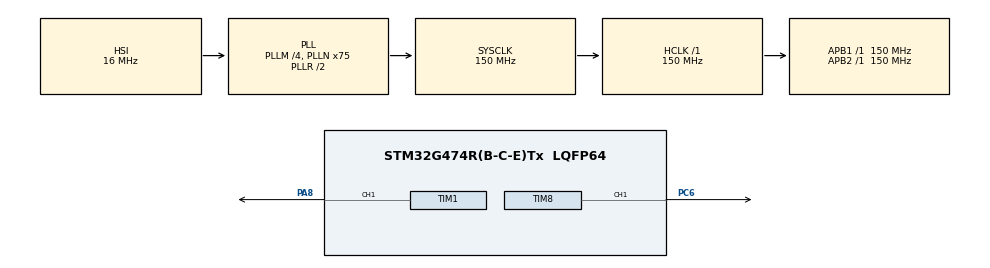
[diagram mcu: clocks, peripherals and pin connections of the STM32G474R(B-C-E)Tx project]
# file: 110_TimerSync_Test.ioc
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Mcu.Family=STM32G4
Mcu.Name=STM32G474R(B-C-E)Tx
Mcu.Package=LQFP64
NVIC.PriorityGroup=NVIC_PRIORITYGROUP_4
PA8.GPIO_ModeDefaultPP=GPIO_MODE_AF_PP
PA8.GPIO_PuPd=GPIO_PULLUP
PA8.Signal=S_TIM1_CH1
PC6.GPIO_ModeDefaultPP=GPIO_MODE_AF_PP
PC6.GPIO_PuPd=GPIO_NOPULL
PC6.Signal=S_TIM8_CH1
PF0-OSC_IN.Mode=HSE-External-Oscillator
PF0-OSC_IN.Signal=RCC_OSC_IN
PF1-OSC_OUT.Mode=HSE-External-Oscillator
PF1-OSC_OUT.Signal=RCC_OSC_OUT
ProjectManager.HeapSize=0x200
ProjectManager.StackSize=0x400
ProjectManager.TargetToolchain=STM32CubeIDE
RCC.ADC12Freq_Value=150000000
RCC.ADC345Freq_Value=150000000
RCC.AHBFreq_Value=150000000
RCC.APB1Freq_Value=150000000
RCC.APB1TimFreq_Value=150000000
RCC.APB2Freq_Value=150000000
RCC.APB2TimFreq_Value=150000000
RCC.CortexFreq_Value=150000000
RCC.EXTERNAL_CLOCK_VALUE=12288000
RCC.HCLKFreq_Value=150000000
RCC.HSE_VALUE=48000000
RCC.HSI48_VALUE=48000000
RCC.HSI_VALUE=16000000
RCC.LSE_VALUE=32768
RCC.PLLM=RCC_PLLM_DIV4
RCC.PLLN=75
RCC.SYSCLKFreq_VALUE=150000000
RCC.SYSCLKSource=RCC_SYSCLKSOURCE_PLLCLK
RCC.USBFreq_Value=150000000
RCC.VCOOutputFreq_Value=300000000
SH.S_TIM1_CH1.0=TIM1_CH1,PWM Generation1 CH1
SH.S_TIM8_CH1.0=TIM8_CH1,PWM Generation1 CH1
TIM1.Channel-PWM\ Generation1\ CH1=TIM_CHANNEL_1
TIM1.CounterMode=TIM_COUNTERMODE_UP
TIM1.OCIdleState_1=TIM_OCIDLESTATE_RESET
TIM1.OCPolarity_1=TIM_OCPOLARITY_LOW
TIM1.PeriodNoDither=1000-1
TIM1.Prescaler=150-1
TIM1.PulseNoDither_1=500-1
TIM1.TIM_MasterOutputTrigger=TIM_TRGO_UPDATE
TIM1.TIM_MasterOutputTrigger2=TIM_TRGO2_RESET
TIM8.Channel-PWM\ Generation1\ CH1=TIM_CHANNEL_1
TIM8.OCIdleState_1=TIM_OCIDLESTATE_RESET
TIM8.OCPolarity_1=TIM_OCPOLARITY_HIGH
TIM8.PeriodNoDither=1000-1
TIM8.Prescaler=15-1
TIM8.PulseNoDither_1=500-1
TIM8.TIM_MasterOutputTrigger=TIM_TRGO_RESET
VP_SYS_VS_DBSignals.Mode=DisableDeadBatterySignals
VP_TIM1_VS_ClockSourceINT.Mode=Internal
VP_TIM8_VS_ClockSourceINT.Mode=Internal
board=custom

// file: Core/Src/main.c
/* USER CODE BEGIN Header */
/**
  ******************************************************************************
  * @file           : main.c
  * @brief          : Main program body
  ******************************************************************************
  * @attention
  *
  * Copyright (c) 2024 STMicroelectronics.
  * All rights reserved.
  *
  * This software is licensed under terms that can be found in the LICENSE file
  * in the root directory of this software component.
  * If no LICENSE file comes with this software, it is provided AS-IS.
  *
  ******************************************************************************
  */
/* USER CODE END Header */
#include "main.h"

TIM_HandleTypeDef htim1;
TIM_HandleTypeDef htim8;

void SystemClock_Config(void);
static void MX_GPIO_Init(void);
static void MX_TIM1_Init(void);
static void MX_TIM8_Init(void);

int main(void)
{

  /* MCU Configuration--------------------------------------------------------*/

  /* Reset of all peripherals, Initializes the Flash interface and the Systick. */
  HAL_Init();

  /* Configure the system clock */
  SystemClock_Config();

  /* Initialize all configured peripherals */
  MX_GPIO_Init();
  MX_TIM1_Init();
  MX_TIM8_Init();
  /* USER CODE BEGIN 2 */
  HAL_TIM_PWM_Start(&htim8, TIM_CHANNEL_1); // Slave Timer
  HAL_Delay(20);
  HAL_TIM_PWM_Start(&htim1, TIM_CHANNEL_1); // Master Timer
  /* USER CODE END 2 */

  /* Infinite loop */
  while (1)
  {

  }
}

void SystemClock_Config(void)
{
  RCC_OscInitTypeDef RCC_OscInitStruct = {0};
  RCC_ClkInitTypeDef RCC_ClkInitStruct = {0};

  /** Configure the main internal regulator output voltage
  */
  HAL_PWREx_ControlVoltageScaling(PWR_REGULATOR_VOLTAGE_SCALE1);

  /** Initializes the RCC Oscillators according to the specified parameters
  * in the RCC_OscInitTypeDef structure.
  */
  RCC_OscInitStruct.OscillatorType = RCC_OSCILLATORTYPE_HSI;
  RCC_OscInitStruct.HSIState = RCC_HSI_ON;
  RCC_OscInitStruct.HSICalibrationValue = RCC_HSICALIBRATION_DEFAULT;
  RCC_OscInitStruct.PLL.PLLState = RCC_PLL_ON;
  RCC_OscInitStruct.PLL.PLLSource = RCC_PLLSOURCE_HSI;
  RCC_OscInitStruct.PLL.PLLM = RCC_PLLM_DIV4;
  RCC_OscInitStruct.PLL.PLLN = 75;
  RCC_OscInitStruct.PLL.PLLP = RCC_PLLP_DIV2;
  RCC_OscInitStruct.PLL.PLLQ = RCC_PLLQ_DIV2;
  RCC_OscInitStruct.PLL.PLLR = RCC_PLLR_DIV2;
  if (HAL_RCC_OscConfig(&RCC_OscInitStruct) != HAL_OK)
  {
    Error_Handler();
  }

  /** Initializes the CPU, AHB and APB buses clocks
  */
  RCC_ClkInitStruct.ClockType = RCC_CLOCKTYPE_HCLK|RCC_CLOCKTYPE_SYSCLK
                              |RCC_CLOCKTYPE_PCLK1|RCC_CLOCKTYPE_PCLK2;
  RCC_ClkInitStruct.SYSCLKSource = RCC_SYSCLKSOURCE_PLLCLK;
  RCC_ClkInitStruct.AHBCLKDivider = RCC_SYSCLK_DIV1;
  RCC_ClkInitStruct.APB1CLKDivider = RCC_HCLK_DIV1;
  RCC_ClkInitStruct.APB2CLKDivider = RCC_HCLK_DIV1;

  if (HAL_RCC_ClockConfig(&RCC_ClkInitStruct, FLASH_LATENCY_4) != HAL_OK)
  {
    Error_Handler();
  }
}

static void MX_TIM1_Init(void)
{

  TIM_ClockConfigTypeDef sClockSourceConfig = {0};
  TIM_MasterConfigTypeDef sMasterConfig = {0};
  TIM_OC_InitTypeDef sConfigOC = {0};
  TIM_BreakDeadTimeConfigTypeDef sBreakDeadTimeConfig = {0};

  htim1.Instance = TIM1;
  htim1.Init.Prescaler = 150-1;
  htim1.Init.CounterMode = TIM_COUNTERMODE_UP;
  htim1.Init.Period = 999;
  htim1.Init.ClockDivision = TIM_CLOCKDIVISION_DIV1;
  htim1.Init.RepetitionCounter = 0;
  htim1.Init.AutoReloadPreload = TIM_AUTORELOAD_PRELOAD_DISABLE;
  if (HAL_TIM_Base_Init(&htim1) != HAL_OK)
  {
    Error_Handler();
  }
  sClockSourceConfig.ClockSource = TIM_CLOCKSOURCE_INTERNAL;
  if (HAL_TIM_ConfigClockSource(&htim1, &sClockSourceConfig) != HAL_OK)
  {
    Error_Handler();
  }
  if (HAL_TIM_PWM_Init(&htim1) != HAL_OK)
  {
    Error_Handler();
  }
  sMasterConfig.MasterOutputTrigger = TIM_TRGO_UPDATE;
  sMasterConfig.MasterOutputTrigger2 = TIM_TRGO2_RESET;
  sMasterConfig.MasterSlaveMode = TIM_MASTERSLAVEMODE_DISABLE;
  if (HAL_TIMEx_MasterConfigSynchronization(&htim1, &sMasterConfig) != HAL_OK)
  {
    Error_Handler();
  }
  sConfigOC.OCMode = TIM_OCMODE_PWM1;
  sConfigOC.Pulse = 499;
  sConfigOC.OCPolarity = TIM_OCPOLARITY_LOW;
  sConfigOC.OCNPolarity = TIM_OCNPOLARITY_HIGH;
  sConfigOC.OCFastMode = TIM_OCFAST_DISABLE;
  sConfigOC.OCIdleState = TIM_OCIDLESTATE_RESET;
  sConfigOC.OCNIdleState = TIM_OCNIDLESTATE_RESET;
  if (HAL_TIM_PWM_ConfigChannel(&htim1, &sConfigOC, TIM_CHANNEL_1) != HAL_OK)
  {
    Error_Handler();
  }
  sBreakDeadTimeConfig.OffStateRunMode = TIM_OSSR_DISABLE;
  sBreakDeadTimeConfig.OffStateIDLEMode = TIM_OSSI_DISABLE;
  sBreakDeadTimeConfig.LockLevel = TIM_LOCKLEVEL_OFF;
  sBreakDeadTimeConfig.DeadTime = 0;
  sBreakDeadTimeConfig.BreakState = TIM_BREAK_DISABLE;
  sBreakDeadTimeConfig.BreakPolarity = TIM_BREAKPOLARITY_HIGH;
  sBreakDeadTimeConfig.BreakFilter = 0;
  sBreakDeadTimeConfig.BreakAFMode = TIM_BREAK_AFMODE_INPUT;
  sBreakDeadTimeConfig.Break2State = TIM_BREAK2_DISABLE;
  sBreakDeadTimeConfig.Break2Polarity = TIM_BREAK2POLARITY_HIGH;
  sBreakDeadTimeConfig.Break2Filter = 0;
  sBreakDeadTimeConfig.Break2AFMode = TIM_BREAK_AFMODE_INPUT;
  sBreakDeadTimeConfig.AutomaticOutput = TIM_AUTOMATICOUTPUT_DISABLE;
  if (HAL_TIMEx_ConfigBreakDeadTime(&htim1, &sBreakDeadTimeConfig) != HAL_OK)
  {
    Error_Handler();
  }
  HAL_TIM_MspPostInit(&htim1);

}

static void MX_TIM8_Init(void)
{

  TIM_ClockConfigTypeDef sClockSourceConfig = {0};
  TIM_MasterConfigTypeDef sMasterConfig = {0};
  TIM_OC_InitTypeDef sConfigOC = {0};
  TIM_BreakDeadTimeConfigTypeDef sBreakDeadTimeConfig = {0};

  htim8.Instance = TIM8;
  htim8.Init.Prescaler = 15-1;
  htim8.Init.CounterMode = TIM_COUNTERMODE_UP;
  htim8.Init.Period = 999;
  htim8.Init.ClockDivision = TIM_CLOCKDIVISION_DIV1;
  htim8.Init.RepetitionCounter = 0;
  htim8.Init.AutoReloadPreload = TIM_AUTORELOAD_PRELOAD_DISABLE;
  if (HAL_TIM_Base_Init(&htim8) != HAL_OK)
  {
    Error_Handler();
  }
  sClockSourceConfig.ClockSource = TIM_CLOCKSOURCE_INTERNAL;
  if (HAL_TIM_ConfigClockSource(&htim8, &sClockSourceConfig) != HAL_OK)
  {
    Error_Handler();
  }
  if (HAL_TIM_PWM_Init(&htim8) != HAL_OK)
  {
    Error_Handler();
  }
  sMasterConfig.MasterOutputTrigger = TIM_TRGO_RESET;
  sMasterConfig.MasterOutputTrigger2 = TIM_TRGO2_RESET;
  sMasterConfig.MasterSlaveMode = TIM_MASTERSLAVEMODE_DISABLE;
  if (HAL_TIMEx_MasterConfigSynchronization(&htim8, &sMasterConfig) != HAL_OK)
  {
    Error_Handler();
  }
  sConfigOC.OCMode = TIM_OCMODE_PWM1;
  sConfigOC.Pulse = 499;
  sConfigOC.OCPolarity = TIM_OCPOLARITY_HIGH;
  sConfigOC.OCNPolarity = TIM_OCNPOLARITY_HIGH;
  sConfigOC.OCFastMode = TIM_OCFAST_DISABLE;
  sConfigOC.OCIdleState = TIM_OCIDLESTATE_RESET;
  sConfigOC.OCNIdleState = TIM_OCNIDLESTATE_RESET;
  if (HAL_TIM_PWM_ConfigChannel(&htim8, &sConfigOC, TIM_CHANNEL_1) != HAL_OK)
  {
    Error_Handler();
  }
  sBreakDeadTimeConfig.OffStateRunMode = TIM_OSSR_DISABLE;
  sBreakDeadTimeConfig.OffStateIDLEMode = TIM_OSSI_DISABLE;
  sBreakDeadTimeConfig.LockLevel = TIM_LOCKLEVEL_OFF;
  sBreakDeadTimeConfig.DeadTime = 0;
  sBreakDeadTimeConfig.BreakState = TIM_BREAK_DISABLE;
  sBreakDeadTimeConfig.BreakPolarity = TIM_BREAKPOLARITY_HIGH;
  sBreakDeadTimeConfig.BreakFilter = 0;
  sBreakDeadTimeConfig.BreakAFMode = TIM_BREAK_AFMODE_INPUT;
  sBreakDeadTimeConfig.Break2State = TIM_BREAK2_DISABLE;
  sBreakDeadTimeConfig.Break2Polarity = TIM_BREAK2POLARITY_HIGH;
  sBreakDeadTimeConfig.Break2Filter = 0;
  sBreakDeadTimeConfig.Break2AFMode = TIM_BREAK_AFMODE_INPUT;
  sBreakDeadTimeConfig.AutomaticOutput = TIM_AUTOMATICOUTPUT_DISABLE;
  if (HAL_TIMEx_ConfigBreakDeadTime(&htim8, &sBreakDeadTimeConfig) != HAL_OK)
  {
    Error_Handler();
  }
  HAL_TIM_MspPostInit(&htim8);

}

static void MX_GPIO_Init(void)
{

  /* GPIO Ports Clock Enable */
  __HAL_RCC_GPIOF_CLK_ENABLE();
  __HAL_RCC_GPIOC_CLK_ENABLE();
  __HAL_RCC_GPIOA_CLK_ENABLE();

}

void Error_Handler(void)
{
  __disable_irq();
  while (1)
  {
  }
}
